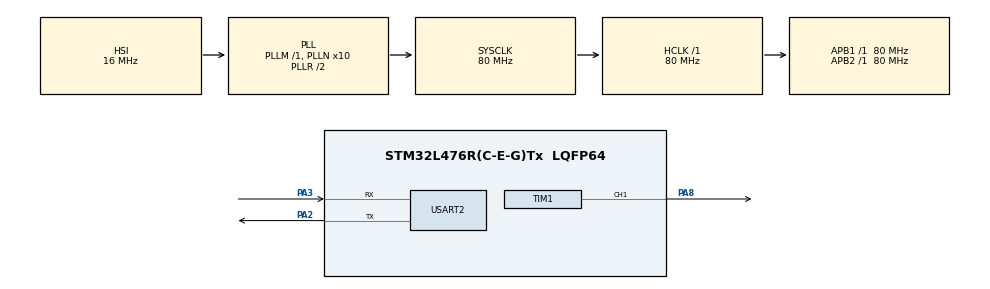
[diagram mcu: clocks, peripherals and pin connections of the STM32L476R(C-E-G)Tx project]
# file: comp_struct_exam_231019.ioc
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Mcu.Family=STM32L4
Mcu.Name=STM32L476R(C-E-G)Tx
Mcu.Package=LQFP64
NVIC.PriorityGroup=NVIC_PRIORITYGROUP_4
NVIC.USART2_IRQn=true\:0\:0\:false\:false\:true\:true\:true\:true
PA2.Mode=Asynchronous
PA2.Signal=USART2_TX
PA3.Mode=Asynchronous
PA3.Signal=USART2_RX
PA8.Signal=S_TIM1_CH1
ProjectManager.HeapSize=0x200
ProjectManager.StackSize=0x400
ProjectManager.TargetToolchain=STM32CubeIDE
RCC.ADCFreq_Value=64000000
RCC.AHBFreq_Value=80000000
RCC.APB1Freq_Value=80000000
RCC.APB1TimFreq_Value=80000000
RCC.APB2Freq_Value=80000000
RCC.APB2TimFreq_Value=80000000
RCC.CortexFreq_Value=80000000
RCC.HCLKFreq_Value=80000000
RCC.HSE_VALUE=8000000
RCC.HSI_VALUE=16000000
RCC.MSI_VALUE=4000000
RCC.PLLN=10
RCC.PLLSourceVirtual=RCC_PLLSOURCE_HSI
RCC.PREFETCH_ENABLE=1
RCC.SYSCLKFreq_VALUE=80000000
RCC.SYSCLKSource=RCC_SYSCLKSOURCE_PLLCLK
RCC.USBFreq_Value=64000000
RCC.VCOOutputFreq_Value=160000000
SH.S_TIM1_CH1.0=TIM1_CH1,PWM Generation1 CH1
TIM1.Channel-PWM\ Generation1\ CH1=TIM_CHANNEL_1
TIM1.Period=100-1
TIM1.Prescaler=8000-1
TIM1.Pulse-PWM\ Generation1\ CH1=50
USART2.VirtualMode-Asynchronous=VM_ASYNC
VP_TIM1_VS_ClockSourceINT.Mode=Internal
board=NUCLEO-L476RG

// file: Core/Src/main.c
/* USER CODE BEGIN Header */
/**
  ******************************************************************************
  * @file           : main.c
  * @brief          : Main program body
  ******************************************************************************
  * @attention
  *
  * Copyright (c) 2023 STMicroelectronics.
  * All rights reserved.
  *
  * This software is licensed under terms that can be found in the LICENSE file
  * in the root directory of this software component.
  * If no LICENSE file comes with this software, it is provided AS-IS.
  *
  ******************************************************************************
  */
/* USER CODE END Header */
#include "main.h"

/* USER CODE BEGIN Includes */
#include <stdio.h>
/* USER CODE END Includes */

TIM_HandleTypeDef htim1;

UART_HandleTypeDef huart2;

/* USER CODE BEGIN PV */
uint8_t rx_data[2];
/* USER CODE END PV */

void SystemClock_Config(void);
static void MX_GPIO_Init(void);
static void MX_TIM1_Init(void);
static void MX_USART2_UART_Init(void);

/* USER CODE BEGIN 0 */
int _write(int file, char *ptr, int len)
{
  HAL_UART_Transmit(&huart2, (uint8_t *)ptr, len, HAL_MAX_DELAY);
  return len;
}

/**
  * @brief  Rx Transfer completed callback.
  * @param  huart UART handle.
  * @retval None
  */
void HAL_UART_RxCpltCallback(UART_HandleTypeDef *huart)
{
	if (rx_data[0] >= '0' && rx_data[0] <= '9' &&
			rx_data[1] >= '0' && rx_data[1] <= '9') {
		uint8_t new_pwm = (rx_data[0] - '0') *10 + (rx_data[1] - '0');
		htim1.Instance->CCR1 = new_pwm;
	}

	HAL_UART_Receive_IT(&huart2, rx_data, 2);
}
/* USER CODE END 0 */

int main(void)
{

  /* MCU Configuration--------------------------------------------------------*/

  /* Reset of all peripherals, Initializes the Flash interface and the Systick. */
  HAL_Init();

  /* Configure the system clock */
  SystemClock_Config();

  /* Initialize all configured peripherals */
  MX_GPIO_Init();
  MX_TIM1_Init();
  MX_USART2_UART_Init();
  /* USER CODE BEGIN 2 */
  /* 1. Control the brightness of an LED using PWM (17%) */
  htim1.Instance->CCR1 = 17;
  HAL_TIM_PWM_Start(&htim1, TIM_CHANNEL_1);

  /* 3. Receive data over USART2 by DMA or interruption */
  HAL_UART_Receive_IT(&huart2, rx_data, 2);
  /* USER CODE END 2 */

  /* Infinite loop */
  /* USER CODE BEGIN WHILE */
  while (1)
  {
	/* 2. Print the PWM value every 1000ms */
	printf("PWM: %ld\r\n", htim1.Instance->CCR1);
	HAL_Delay(1000);
    /* USER CODE END WHILE */

  }
}

void SystemClock_Config(void)
{
  RCC_OscInitTypeDef RCC_OscInitStruct = {0};
  RCC_ClkInitTypeDef RCC_ClkInitStruct = {0};

  /** Configure the main internal regulator output voltage
  */
  if (HAL_PWREx_ControlVoltageScaling(PWR_REGULATOR_VOLTAGE_SCALE1) != HAL_OK)
  {
    Error_Handler();
  }

  /** Initializes the RCC Oscillators according to the specified parameters
  * in the RCC_OscInitTypeDef structure.
  */
  RCC_OscInitStruct.OscillatorType = RCC_OSCILLATORTYPE_HSI;
  RCC_OscInitStruct.HSIState = RCC_HSI_ON;
  RCC_OscInitStruct.HSICalibrationValue = RCC_HSICALIBRATION_DEFAULT;
  RCC_OscInitStruct.PLL.PLLState = RCC_PLL_ON;
  RCC_OscInitStruct.PLL.PLLSource = RCC_PLLSOURCE_HSI;
  RCC_OscInitStruct.PLL.PLLM = 1;
  RCC_OscInitStruct.PLL.PLLN = 10;
  RCC_OscInitStruct.PLL.PLLP = RCC_PLLP_DIV7;
  RCC_OscInitStruct.PLL.PLLQ = RCC_PLLQ_DIV2;
  RCC_OscInitStruct.PLL.PLLR = RCC_PLLR_DIV2;
  if (HAL_RCC_OscConfig(&RCC_OscInitStruct) != HAL_OK)
  {
    Error_Handler();
  }

  /** Initializes the CPU, AHB and APB buses clocks
  */
  RCC_ClkInitStruct.ClockType = RCC_CLOCKTYPE_HCLK|RCC_CLOCKTYPE_SYSCLK
                              |RCC_CLOCKTYPE_PCLK1|RCC_CLOCKTYPE_PCLK2;
  RCC_ClkInitStruct.SYSCLKSource = RCC_SYSCLKSOURCE_PLLCLK;
  RCC_ClkInitStruct.AHBCLKDivider = RCC_SYSCLK_DIV1;
  RCC_ClkInitStruct.APB1CLKDivider = RCC_HCLK_DIV1;
  RCC_ClkInitStruct.APB2CLKDivider = RCC_HCLK_DIV1;

  if (HAL_RCC_ClockConfig(&RCC_ClkInitStruct, FLASH_LATENCY_4) != HAL_OK)
  {
    Error_Handler();
  }
}

static void MX_TIM1_Init(void)
{

  TIM_ClockConfigTypeDef sClockSourceConfig = {0};
  TIM_MasterConfigTypeDef sMasterConfig = {0};
  TIM_OC_InitTypeDef sConfigOC = {0};
  TIM_BreakDeadTimeConfigTypeDef sBreakDeadTimeConfig = {0};

  htim1.Instance = TIM1;
  htim1.Init.Prescaler = 8000-1;
  htim1.Init.CounterMode = TIM_COUNTERMODE_UP;
  htim1.Init.Period = 100-1;
  htim1.Init.ClockDivision = TIM_CLOCKDIVISION_DIV1;
  htim1.Init.RepetitionCounter = 0;
  htim1.Init.AutoReloadPreload = TIM_AUTORELOAD_PRELOAD_DISABLE;
  if (HAL_TIM_Base_Init(&htim1) != HAL_OK)
  {
    Error_Handler();
  }
  sClockSourceConfig.ClockSource = TIM_CLOCKSOURCE_INTERNAL;
  if (HAL_TIM_ConfigClockSource(&htim1, &sClockSourceConfig) != HAL_OK)
  {
    Error_Handler();
  }
  if (HAL_TIM_PWM_Init(&htim1) != HAL_OK)
  {
    Error_Handler();
  }
  sMasterConfig.MasterOutputTrigger = TIM_TRGO_RESET;
  sMasterConfig.MasterOutputTrigger2 = TIM_TRGO2_RESET;
  sMasterConfig.MasterSlaveMode = TIM_MASTERSLAVEMODE_DISABLE;
  if (HAL_TIMEx_MasterConfigSynchronization(&htim1, &sMasterConfig) != HAL_OK)
  {
    Error_Handler();
  }
  sConfigOC.OCMode = TIM_OCMODE_PWM1;
  sConfigOC.Pulse = 50;
  sConfigOC.OCPolarity = TIM_OCPOLARITY_HIGH;
  sConfigOC.OCNPolarity = TIM_OCNPOLARITY_HIGH;
  sConfigOC.OCFastMode = TIM_OCFAST_DISABLE;
  sConfigOC.OCIdleState = TIM_OCIDLESTATE_RESET;
  sConfigOC.OCNIdleState = TIM_OCNIDLESTATE_RESET;
  if (HAL_TIM_PWM_ConfigChannel(&htim1, &sConfigOC, TIM_CHANNEL_1) != HAL_OK)
  {
    Error_Handler();
  }
  sBreakDeadTimeConfig.OffStateRunMode = TIM_OSSR_DISABLE;
  sBreakDeadTimeConfig.OffStateIDLEMode = TIM_OSSI_DISABLE;
  sBreakDeadTimeConfig.LockLevel = TIM_LOCKLEVEL_OFF;
  sBreakDeadTimeConfig.DeadTime = 0;
  sBreakDeadTimeConfig.BreakState = TIM_BREAK_DISABLE;
  sBreakDeadTimeConfig.BreakPolarity = TIM_BREAKPOLARITY_HIGH;
  sBreakDeadTimeConfig.BreakFilter = 0;
  sBreakDeadTimeConfig.Break2State = TIM_BREAK2_DISABLE;
  sBreakDeadTimeConfig.Break2Polarity = TIM_BREAK2POLARITY_HIGH;
  sBreakDeadTimeConfig.Break2Filter = 0;
  sBreakDeadTimeConfig.AutomaticOutput = TIM_AUTOMATICOUTPUT_DISABLE;
  if (HAL_TIMEx_ConfigBreakDeadTime(&htim1, &sBreakDeadTimeConfig) != HAL_OK)
  {
    Error_Handler();
  }
  HAL_TIM_MspPostInit(&htim1);

}

static void MX_USART2_UART_Init(void)
{

  huart2.Instance = USART2;
  huart2.Init.BaudRate = 115200;
  huart2.Init.WordLength = UART_WORDLENGTH_8B;
  huart2.Init.StopBits = UART_STOPBITS_1;
  huart2.Init.Parity = UART_PARITY_NONE;
  huart2.Init.Mode = UART_MODE_TX_RX;
  huart2.Init.HwFlowCtl = UART_HWCONTROL_NONE;
  huart2.Init.OverSampling = UART_OVERSAMPLING_16;
  huart2.Init.OneBitSampling = UART_ONE_BIT_SAMPLE_DISABLE;
  huart2.AdvancedInit.AdvFeatureInit = UART_ADVFEATURE_NO_INIT;
  if (HAL_UART_Init(&huart2) != HAL_OK)
  {
    Error_Handler();
  }

}

static void MX_GPIO_Init(void)
{

  /* GPIO Ports Clock Enable */
  __HAL_RCC_GPIOA_CLK_ENABLE();

}

void Error_Handler(void)
{
  __disable_irq();
  while (1)
  {
  }
}
